# apollo510 register map
Vendor: Ambiq Micro; Series: Apollo; File version: 1.0
CPU: CM55 r1p1, little endian, MPU, FPU, double-precision FPU, DSP, I-cache, D-cache, VTOR, ITCM, DTCM, 4 interrupt priority bits, 0 interrupts, 8 SAU regions
Registers are 32-bit, read-write, reset 0x0 unless marked. A register's access mark holds for its fields unless they carry their own. Offsets are from the block's base; [hi:lo] are bit positions; {n}, {i} and the like mark numbered series.

## USBPHY — USBPHY device register descriptions.
Base 0x400B4000
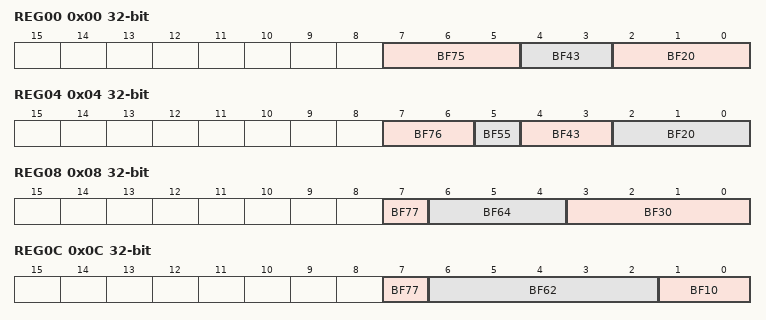
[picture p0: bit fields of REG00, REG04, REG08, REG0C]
0x00 REG00 — Register description here
  [7:5] BF75 — Manually set the Rx Clock phase select. These bits will tune the HS RX path sample timing between digital and analog inside PHY: 3'b000 represents the earliest phase 3'b111 represents the latest phase The delay associated with each step is 256ps
  [4:3] BF43 — BG observation enable signal. Active low. When enabled, vref 400mV can be observed through USB0PP/USB0PN
  [2:0] BF20 — This bitfield is reserved.
0x04 REG04 — Register description here
  [7:6] BF76 — disconnect detector bias current tuning
  [5] BF55 — This bitfield is reserved.
  [4:3] BF43 — Squelch detector bias current tuning, 2'b00 represents the minimum bias current 2'b11 represents the maximum bias current
  [2:0] BF20 — Manually set the Tx Clock phase select. These bits will tune the HS TX path sample timing between digital and analog inside PHY 3'b000 represents the earliest phase 3'b111 represents the latest phase The delay associated with each step is 256ps
0x08 REG08 — Register description here
  [7] BF77 — digital squelch filter select, this bit is used to filter the glitch on the HS RX squelch signal. 1: 1 clock cycle filter 0: 2 clock cycle fitter
  [6:4] BF64 — HS eye height tuning 3'b000:400mV(default) 3'b001:475mV 3'b010:350mV 3'b011:500mV 3'b100:412.5mV 3'b101:425mV 3'b110:437.5mV 3'b111:450mV
  [3:0] BF30 — 2'b00 represents the minimum bias current 2'b11 represents the maximum bias current Rx squelch trigger point configures. Allows tuning of the squelch trigger point in order to compensate for package and board level parasitic. 4'b0000:112.5mV 4'b0001:150mV 4'b0010:87.5mV 4'b0011:162.5mV 4'b0100:100mV 4'b0101:137.5mV 4'b0110:75mV 4'b0111:150mV 4'b1000:125mV 4'b1001:162.5mV 4'b1010:100mV 4'b1011:175mV 4'b1100:150mV(default) 4'b1101:187.5mV 4'b1110:125mV 4'b1111:200mV
0x0C REG0C — Register description here
  [7] BF77 — This bitfield is reserved.
  [6:2] BF62 — 45ohm HS ODT value tuning and FS/LS driver strength tuning 5'b11111: smallest HS ODT value and largest FS/LS driver strength and fastest FS/LS slew rate 5'b10000: biggest HS ODT value and smallest FS/LS driver strength and slowest FS/LS slew rate
  [1:0] BF10 — BG output voltage reference adjust, normally these bits are recommended to be kept as the default values. 00: standard center level around 1.25v output, recommended 01: relative higher output 1x: relative higher output
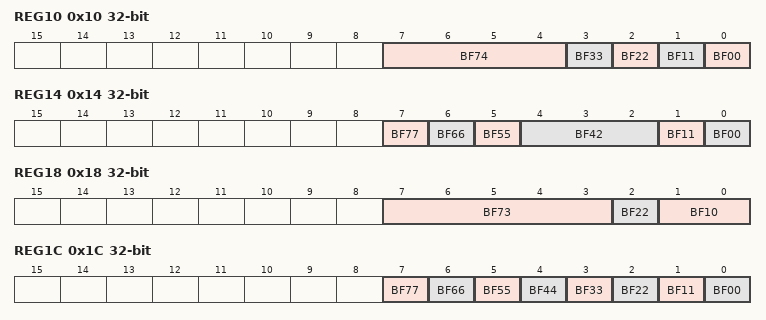
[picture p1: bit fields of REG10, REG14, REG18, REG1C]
0x10 REG10 — Register description here
  [7:4] BF74 — HOST disconnect detection trigger point. Only valid in host mode. Allows compensation for package and board level parasitics which tend to drop in the input voltage. 4'b0000:625mV 4'b0001:675mV 4'b0010:612.5mV 4'b0011:575mV 4'b0100:550mV 4'b0101:600mV (default) 4'b0110:537.5mV 4'b0111:500mV 4'b1000:600mV 4'b1001:650mV 4'b1010:587.5mV 4'b1011:550mV 4'b1100:575mV 4'b1101:625mV 4'b1110:562.5mV 4'b1111:525mV
  [3] BF33 — Single ended disconnect detection enable, active high. 1: enable Single ended disconnect detection 0: disenable Single ended disconnect detection
  [2] BF22 — Half bit pre-emphasis enable. Active high 1: half bit pre-emphasize mode, recommended 0: full bit pre-emphasize mode
  [1] BF11 — Turn off LS/FS differential receiver in suspend mode, active low 1: keep the LS/FS differential receiver , pin fss_rxrcv will toggling according to the DP/DM state 0: turn off the LS/FS differential receiver, pin fss_rxrcv will not toggling according to the DP/DM state
  [0] BF00 — Bypass squelch trigger point configure in chirp modes , active high, keep the default value is strongly recommended . 1: Bypass squelch trigger point configure in chirp modes , 0: squelch trigger point set to 250mV in chirp modes.
0x14 REG14 — Register description here
  [7] BF77 — This bitfield is reserved.
  [6] BF66 — FIXME (description needed).
  [5] BF55 — PLL feedback divider ratio option.
    0=DIV40 (PLL feedback clock divided by 40.); 1=DIV20 (PLL feedback clock divided by 20.)
  [4:2] BF42 — Tx HS pre-emphasis strength 3'b111 represents the strongest , 3'b000 the weakest
  [1] BF11 — PLL bandwidth option 1'b0 default 1'b1 increases the PLL bandwidth
  [0] BF00 — Dflop output select signal delay compared with digital clock enable signal 1'b0:3 clocks 1'b1:2 clocks
0x18 REG18 — Register description here
  [7:3] BF73 — This bitfield is reserved.
  [2] BF22 — Clk60m, clk12m and clk48m enable. 1'b0:disables the clocks 1'b1:enables the clocks
  [1:0] BF10 — HS receiver bias current tuning. 2'b00 represents the minimum bias current 2'b11 represents the maximum bias current
0x1C REG1C — Register description here
  [7] BF77 — This bitfield is reserved.
  [6] BF66 — This bitfield is reserved.
  [5] BF55 — BG power down control bit, active high 1: power down band-gap 0: normal operation mode
  [4] BF44 — 480M clock out enable. 1'b0:pll disable 1'b1: 480M clock out enable 1'b0: 480M clock out disable
  [3] BF33 — PLL enable value from suspend module. 1'b1:pll enable
  [2] BF22 — PLL enable bypass from suspend module. 1'b1: bypass enable 1'b0:bypass disable
  [1] BF11 — Tx power down in suspend state. Active low.
  [0] BF00 — Set IO high-Z state. Active high
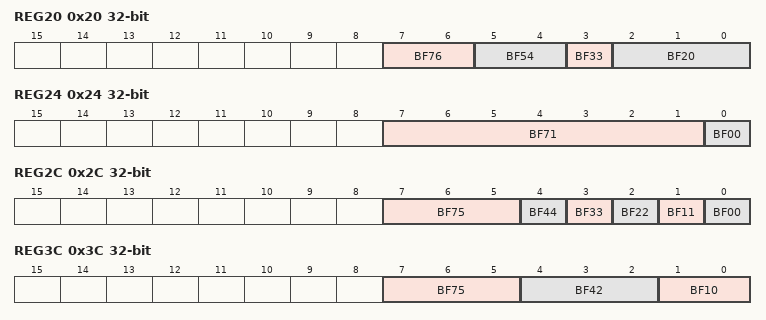
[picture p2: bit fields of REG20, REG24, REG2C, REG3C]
0x20 REG20 — Register description here
  [7:6] BF76 — This bitfield is reserved.
  [5:4] BF54 — Analog observation port select. for detailed information, please refer to section 10.3 , Table 30 : Debug and OBS port
  [3] BF33 — This bitfield is reserved.
  [2:0] BF20 — Rx enable delay select. 3'b000: 4 clocks (480Mhz clock) 3'b001: 5 clocks 3'b010: 6 clocks 3'b011: 7 clocks 3'b100: 8 clocks 3'b101: 9 clocks 3'b110: 10 clocks 3'b111: 12 clocks
0x24 REG24 — Register description here
  [7:1] BF71 — This bitfield is reserved.
  [0] BF00 — it0
0x28 REG28 — Register description here
  [7:0] BF70 — This bitfield is reserved.
0x2C REG2C — Register description here
  [7:5] BF75 — This bitfield is reserved.
  [4] BF44 — This bitfield is reserved.
  [3] BF33 — This bitfield is reserved.
  [2] BF22 — HS keep alive enable. 1'b1: HS keep alive enable 1'b0: HS keep alive disable
  [1] BF11 — This bitfield is reserved.
  [0] BF00 — All port z bypass value. 1'b1: bypass enable 1'b0:bypass disable
0x30 REG30 — Register description here
  [7:0] BF70 — This bitfield is reserved.
0x34 REG34 — Register description here
  [7:0] BF70 — FIXME (description needed).
0x38 REG38 — Register description here
  [7:0] BF70 — This bitfield is reserved.
0x3C REG3C — Register description here
  [7:5] BF75 — Host disconnect filter select. 3'b100:6 clocks(480M clock) 3'b101:8 clocks 3'b111:disconnect disable Other: invalid
  [4:2] BF42 — This bitfield is reserved.
  [1:0] BF10 — FIXME (description needed).
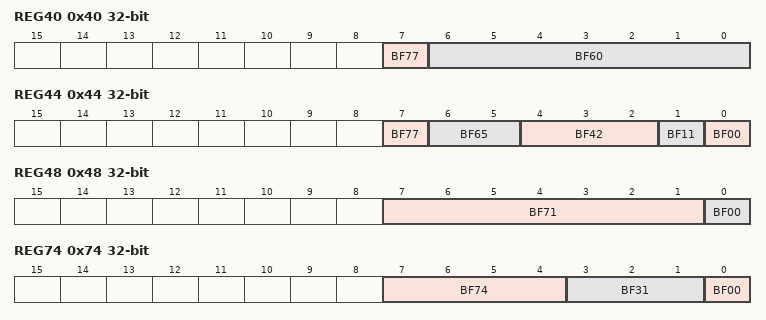
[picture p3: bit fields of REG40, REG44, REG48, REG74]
0x40 REG40 — Register description here
  [7] BF77 — This bitfield is reserved.
  [6:0] BF60 — This bitfield is reserved.
0x44 REG44 — Register description here
  [7] BF77 — This bitfield is reserved.
  [6:5] BF65 — This bitfield is reserved.
  [4:2] BF42 — This bitfield is reserved.
  [1] BF11 — Disconnect squelch and comparator calibration bypass, active high
  [0] BF00 — 1: DP/DM will be sampled in HS Tx or Rx state 0: DP/DM will be sampled only in Hs Rx state
0x48 REG48 — Register description here
  [7:1] BF71 — This bitfield is reserved.
  [0] BF00 — Enable TX shutdown, active LOW. This bit is only used for debug purpose , nothing to do with the normal operation and signal quality, keeping the default value is strongly recommended.
{0xC+0x10*i} REG{i}C (i=4..6) — Register description here
  [7:0] BF70 — This bitfield is reserved.
0x50 REG50 — Register description here
  [7:0] BF70 — This bitfield is reserved.
0x54 REG54 — Register description here
  [7:0] BF70 — This bitfield is reserved.
0x58 REG58 — Register description here
  [7:0] BF70 — This bitfield is reserved.
0x60 REG60 — Register description here
  [7:0] BF70 — This bitfield is reserved.
0x64 REG64 — Register description here
  [0] BF00 — This bitfield is reserved.
0x68 REG68 — Register description here
  [7:0] BF70 — This bitfield is reserved.
0x70 REG70 — Register description here
  [7:0] BF70 — FIXME (description needed).
0x74 REG74 — Register description here
  [7:4] BF74 — This bitfield is reserved.
  [3:1] BF31 — HS driver slew rate tuning 001:SR is weakest 111:SR is strongest.000 is forbidden.
  [0] BF00 — Disconnect detection block input res load sel. 1'b0: disconnect detection block input res load bypass 1'b1: disconnect detection block input res load enable
0x78 REG78 — Register description here
  [7:0] BF70 — This bitfield is reserved.
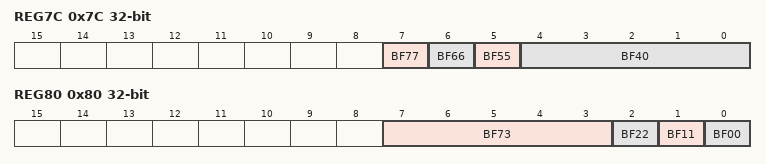
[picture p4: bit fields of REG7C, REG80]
0x7C REG7C — Register description here
  [7] BF77 — Clk60m source clock select. 1'b1: free clock 60M 1'b0: utmi_clk
  [6] BF66 — Hs chirp mode amplitude increasing register, active high.
  [5] BF55 — No leakage current on DP/DM pin when VCCA3P3 power down, active low. Keeping the default value was greatly appreciated
  [4:0] BF40 — This bitfield is reserved.
0x80 REG80 — Register description here
  [7:3] BF73 — This bitfield is reserved.
  [2] BF22 — utmi clock always on 1'b1: utmi clock always on 1'b0: utmi clock relative to suspendm
  [1] BF11 — Digital clock enable bypass value 1'b1: digital clock enable 1'b0: digital clock disable
  [0] BF00 — Digital clock enable bypass 1'b1: digital clock bypass enable 1'b0: digital clock bypass disable
0x84 REG84 — Register description here
  [7:0] BF70 — This bitfield is reserved.
